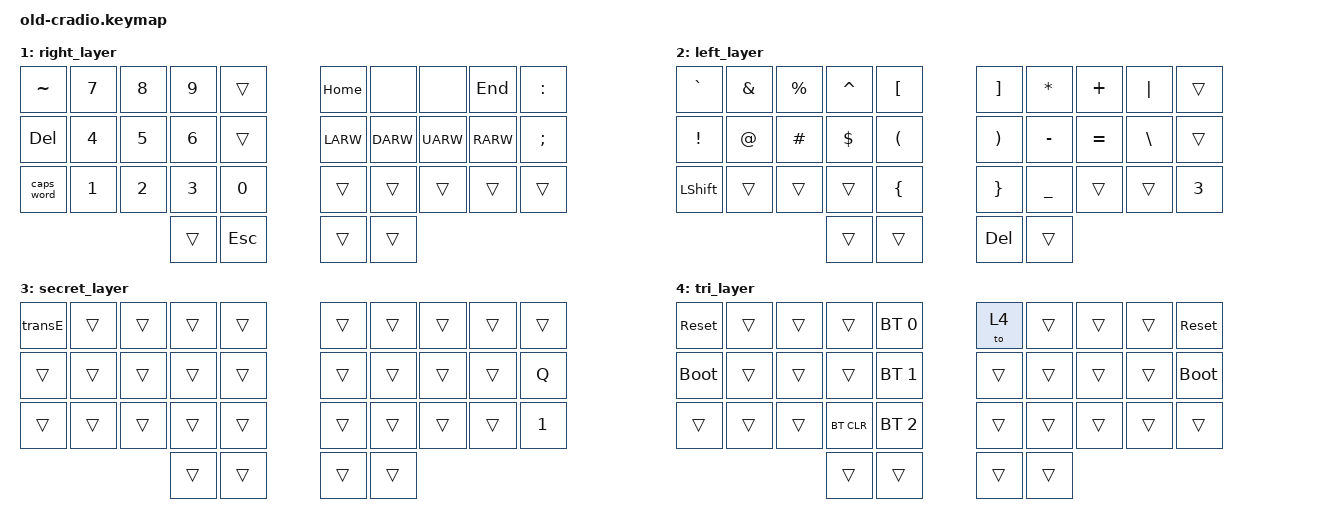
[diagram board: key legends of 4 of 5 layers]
// Copyright (c) 2022 The ZMK Contributors
// SPDX-License-Identifier: MIT

#include <behaviors.dtsi>
#include <dt-bindings/zmk/keys.h>
#include <dt-bindings/zmk/bt.h>

// Home row mods macr
#define HRML(k1,k2,k3) &ht LCTRL k1  &ht LALT k2  &ht LGUI k3
#define HRMR(k1,k2,k3) &ht LGUI k1  &ht RALT k2  &ht RCTRL k3


/ {
    behaviors {
        ht: hold_tap {
            label = "hold_tap";
            compatible = "zmk,behavior-hold-tap";
            #binding-cells = <2>;
            flavor = "tap-preferred";
            tapping-term-ms = <200>;
            quick-tap-ms = <200>;
            global-quick-tap;
            bindings = <&kp>, <&kp>;
        };
    };

    behaviors {
        htes: hold_tap_enter_shift {
            label = "hold_tap_enter_shift";
            compatible = "zmk,behavior-hold-tap";
            #binding-cells = <2>;
            flavor = "tap-preferred";
            tapping-term-ms = <200>;
            quick-tap-ms = <200>;
            global-quick-tap;
            bindings = <&kp>, <&kp>;
        };
    };

    conditional_layers {
        compatible = "zmk,conditional-layers";
        tri_layer {
            if-layers = <1 2>;
            then-layer = <4>;
        };
    };

    keymap {
        compatible = "zmk,keymap";
        default_layer {
            bindings = <
        //╭──────────┬──────────┬──────────┬──────────┬──────────╮   ╭──────────┬──────────┬──────────┬──────────┬──────────╮
        //│  Q       │  W       │  E       │  R       │  T       │   │  Y       │  U       │  I       │  O       │  P       │
            &kp Q      &kp W      &kp E      &kp R      &kp T          &kp Y      &kp U      &kp I      &kp O      &kp P
        //├──────────┼──────────┼──────────┼──────────┼──────────┤   ├──────────┼──────────┼──────────┼──────────┼──────────┤
        //│  A       │  S       │  D       │  F       │  G       │   │  H       │  J       │  K       │  L       │ ' "      │
        &htes LSHFT A   HRML(S,     D,         F)     &kp G          &kp H        HRMR(J,        K,         L)    &htes RSHFT SQT
        //├──────────┼──────────┼──────────┼──────────┼──────────┤   ├──────────┼──────────┼──────────┼──────────┼──────────┤
        //│  Z       │  X       │  C       │  V       │  B       │   │  N       │  M       │ , <      │ . >      │ / ?      │
            &kp Z      &kp X      &kp C      &kp V      &kp B          &kp N      &kp M      &kp COMMA  &kp DOT    &kp FSLH
        //╰──────────┴──────────┴──────────┼──────────┼──────────┤   ├──────────┼──────────┼──────────┴──────────┴──────────╯
                                            &lt 2 TAB   &kp SPACE     &kp BSPC  &lt 1 ENTER
        //                                 ╰──────────┴──────────╯   ╰──────────┴──────────╯
            >;
        };

        right_layer {
            bindings = <
        //╭──────────┬──────────┬──────────┬──────────┬──────────╮   ╭──────────┬──────────┬──────────┬──────────┬──────────╮
        //│   ~      │  7       │  8       │  9       │          │   │ HOME     | PAGE DWN | PAGE UP  │ END      │  :       │
            &kp TILDE   &kp N7     &kp N8     &kp N9     &trans         &kp HOME    &none      &none     &kp END   &kp COLON
        //├──────────┼──────────┼──────────┼──────────┼──────────┤   ├──────────┼──────────┼──────────┼──────────┼──────────┤
        //│ DELETE   │  4       │  5       │  6       │          │   │ LEFT     │ DOWN     │ UP       │ RIGHT    │  ;       │
            &kp DEL    &kp N4     &kp N5     &kp N6     &trans         &kp LARW   &kp DARW   &kp UARW    &kp RARW   &kp SEMI
        //├──────────┼──────────┼──────────┼──────────┼──────────┤   ├──────────┼──────────┼──────────┼──────────┼──────────┤
        //│ CAPS     │  1       │  2       │  3       │  0       │   │          │          │          │          │          │
           &caps_word  &kp N1     &kp N2     &kp N3     &kp N0         &trans     &trans     &trans     &trans     &trans
        //╰──────────┴──────────┴──────────┼──────────┼──────────┤   ├──────────┼──────────┼──────────┴──────────┴──────────╯
                                             &trans      &kp ESC        &trans     &trans
        //                                 ╰──────────┴──────────╯   ╰──────────┴──────────╯
            >;
        };

    //    left_layer {
    //        bindings = <
        //╭──────────┬──────────┬──────────┬──────────┬──────────╮   ╭──────────┬──────────┬──────────┬──────────┬──────────╮
        //│   `      │  [       │  {       │  }       │          │   │  ^       │  (       │  )       │  ]       │          │
   //         &kp GRAVE  &kp LBKT   &kp LBRC   &kp RBRC   &trans         &kp CARET  &kp LPAR   &kp RPAR   &kp RBKT   &trans
        //├──────────┼──────────┼──────────┼──────────┼──────────┤   ├──────────┼──────────┼──────────┼──────────┼──────────┤
        //│  !       │  @       │  #       │  $       │  %       │   │  *       │  -       │  =       │  \       │          │
  //          &kp EXCL   &kp AT     &kp HASH   &kp DLLR   &kp PRCNT      &kp ASTRK  &kp MINUS  &kp EQUAL  &kp BSLH   &trans
        //├──────────┼──────────┼──────────┼──────────┼──────────┤   ├──────────┼──────────┼──────────┼──────────┼──────────┤
        //│          │          │          │          │          │   │  &       │  _       │  +       │  │       │          │
 //           &trans     &trans     &trans     &trans     &trans         &kp AMPS   &kp UNDER  &kp PLUS   &kp PIPE   &trans
        //╰──────────┴──────────┴──────────┼──────────┼──────────┤   ├──────────┼──────────┼──────────┴──────────┴──────────╯
//                                                                  macro ctrl+BSPC macro ctrl+DELETE
 //                                            &trans     &trans       &kp DEL     &trans
 //       //                                 ╰──────────┴──────────╯   ╰──────────┴──────────╯
 //           >;
 //       };

        left_layer {
            bindings = <
        //╭──────────┬──────────┬──────────┬──────────┬──────────╮   ╭──────────┬──────────┬──────────┬──────────┬──────────╮
        //│   `      │    &     │     %    │    ^     │    [     │   │    ]     │    *     │    +     │    |     │          │
            &kp GRAVE  &kp AMPS  &kp PRCNT  &kp CARET   &kp LBKT       &kp RBKT   &kp ASTRK  &kp PLUS   &kp PIPE   &trans
        //├──────────┼──────────┼──────────┼──────────┼──────────┤   ├──────────┼──────────┼──────────┼──────────┼──────────┤
        //│  !       │  @       │  #       │  $       │    (     │   │    )     │  -       │    =     │    \     │          │
            &kp EXCL   &kp AT     &kp HASH   &kp DLLR   &kp LPAR       &kp RPAR   &kp MINUS  &kp EQUAL  &kp BSLH   &trans
        //├──────────┼──────────┼──────────┼──────────┼──────────┤   ├──────────┼──────────┼──────────┼──────────┼──────────┤
        //│          │          │          │          │    {     │   │    }     │  _       │          │          │          │
            &kp LSHFT   &trans     &trans     &trans    &kp LBRC       &kp RBRC   &kp UNDER  &trans     &trans     &kp 3
        //╰──────────┴──────────┴──────────┼──────────┼──────────┤   ├──────────┼──────────┼──────────┴──────────┴──────────╯
//                                                                  macro ctrl+BSPC macro ctrl+DELETE
                                             &trans     &trans       &kp DEL     &trans
        //                                 ╰──────────┴──────────╯   ╰──────────┴──────────╯
            >;
        };

        secret_layer {
            bindings = <
        //╭──────────┬──────────┬──────────┬──────────┬──────────╮   ╭──────────┬──────────┬──────────┬──────────┬──────────╮
        //│   `      │    &     │     %    │    ^     │    [     │   │    ]     │    *     │    +     │    |     │          │
            &transE  &trans  &trans  &trans   &trans       &trans   &trans  &trans   &trans   &trans
        //├──────────┼──────────┼──────────┼──────────┼──────────┤   ├──────────┼──────────┼──────────┼──────────┼──────────┤
        //│  !       │  @       │  #       │  $       │    (     │   │    )     │  -       │    =     │    \     │          │
            &trans      &trans    &trans   &trans   &trans       &trans   &trans  &trans  &trans   &kp Q
        //├──────────┼──────────┼──────────┼──────────┼──────────┤   ├──────────┼──────────┼──────────┼──────────┼──────────┤
        //│          │          │          │          │    {     │   │    }     │  _       │          │          │          │
            &trans   &trans     &trans     &trans    &trans       &trans   &trans  &trans     &trans     &kp 1
        //╰──────────┴──────────┴──────────┼──────────┼──────────┤   ├──────────┼──────────┼──────────┴──────────┴──────────╯
//                                                                  macro ctrl+BSPC macro ctrl+DELETE
                                             &trans     &trans       &trans     &trans
        //                                 ╰──────────┴──────────╯   ╰──────────┴──────────╯
            >;
        };

        tri_layer {
            bindings = <
        //╭──────────┬──────────┬──────────┬──────────┬──────────╮   ╭──────────┬──────────┬──────────┬──────────┬──────────╮
        //│ RESET    │          │          │          │PROFILE 0 │   │          │          │          │          │  RESET   │
          &sys_reset   &trans     &trans     &trans    &bt BT_SEL 0    &to 4     &trans     &trans     &trans    &sys_reset
        //├──────────┼──────────┼──────────┼──────────┼──────────┤   ├──────────┼──────────┼──────────┼──────────┼──────────┤
        //│BOOTLOADER│          │          │          │PROFILE 1 │   │          │          │          │          │BOOTLOADER│
          &bootloader  &trans     &trans     &trans    &bt BT_SEL 1    &trans     &trans     &trans     &trans    &bootloader
        //├──────────┼──────────┼──────────┼──────────┼──────────┤   ├──────────┼──────────┼──────────┼──────────┼──────────┤
        //│          │          │          │ CLEAR BT │PROFILE 2 │   │          │          │          │          │          │
            &trans     &trans     &trans    &bt BT_CLR &bt BT_SEL 2    &trans     &trans     &trans     &trans     &trans
        //╰──────────┴──────────┴──────────┼──────────┼──────────┤   ├──────────┼──────────┼──────────┴──────────┴──────────╯
                                             &trans     &trans         &trans     &trans
        //                                 ╰──────────┴──────────╯   ╰──────────┴──────────╯
            >;
        };
    };
};

